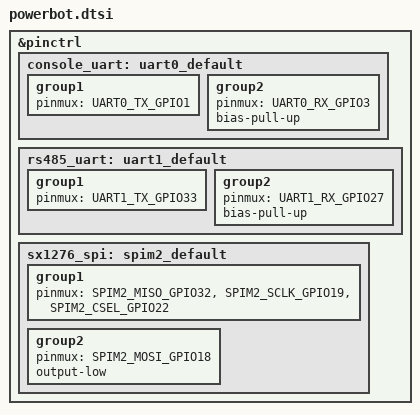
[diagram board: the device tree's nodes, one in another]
/*
 * Copyright (c) 2022 Espressif Systems (Shanghai) Co., Ltd.
 *
 * SPDX-License-Identifier: Apache-2.0
 */

#include <zephyr/dt-bindings/pinctrl/esp-pinctrl-common.h>
#include <dt-bindings/pinctrl/esp32-pinctrl.h>
#include <zephyr/dt-bindings/pinctrl/esp32-gpio-sigmap.h>

&pinctrl {

	console_uart: uart0_default {
		group1 {
			pinmux = <UART0_TX_GPIO1>;
		};
		group2 {
			pinmux = <UART0_RX_GPIO3>;
			bias-pull-up;
		};
	};

	rs485_uart: uart1_default {
		group1 {
			pinmux = <UART1_TX_GPIO33>;
		};
		group2 {
			pinmux = <UART1_RX_GPIO27>;
			bias-pull-up;
		};
	};

	sx1276_spi: spim2_default {
		group1 {
			pinmux = <SPIM2_MISO_GPIO32>,
				 <SPIM2_SCLK_GPIO19>,
				 <SPIM2_CSEL_GPIO22>;
		};
		group2 {
			pinmux = <SPIM2_MOSI_GPIO18>;
			output-low;
		};
	};
};
